# USCI_B0__SPI_Mode_1 register map
Vendor: Texas Instruments
Peripheral module from a debugger description file (folder msp430).
Registers are 8-bit, access not given, no defined reset value unless marked. A register's access mark holds for its fields unless they carry their own. Offsets are as the file gives them; lines under a group give offsets from that group; [hi:lo] are bit positions; {n}, {i} and the like mark numbered series; 'fields as' and 'values as' point back to an identical list; <NAME> marks a mode.

## USCI_B0_SPI_Mode
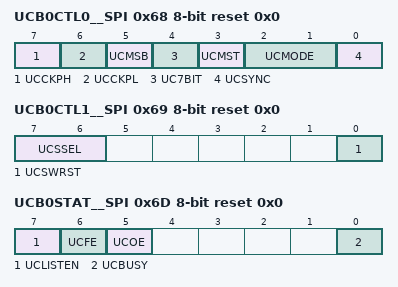
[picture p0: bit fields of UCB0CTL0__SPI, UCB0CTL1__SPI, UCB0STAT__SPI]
0x68 UCB0CTL0__SPI rw reset 0x0 — USCI B0 Control Register 0
  [7] UCCKPH — Sync. Mode: Clock Phase
  [6] UCCKPL — Sync. Mode: Clock Polarity
  [5] UCMSB — Sync. Mode: MSB first 0:LSB / 1:MSB
  [4] UC7BIT — Sync. Mode: Data Bits 0:8-bits / 1:7-bits
  [3] UCMST — Sync. Mode: Master Select
  [2:1] UCMODE — Sync. Mode: USCI Mode 1
    {v}=Sync. Mode: USCI Mode: {v} (v=0..3)
  [0] UCSYNC — Sync-Mode 0:UART-Mode / 1:SPI-Mode
0x69 UCB0CTL1__SPI rw reset 0x0 — USCI B0 Control Register 1
  [7:6] UCSSEL — USCI 1 Clock Source Select 1
    {v}=USCI 0 Clock Source: {v} (v=0..3)
  [0] UCSWRST — USCI Software Reset
0x6A UCB0BR0__SPI — USCI B0 Baud Rate 0
0x6B UCB0BR1__SPI — USCI B0 Baud Rate 1
0x6D UCB0STAT__SPI rw reset 0x0 — USCI B0 Status Register
  [7] UCLISTEN — USCI Listen mode
  [6] UCFE — USCI Frame Error Flag
  [5] UCOE — USCI Overrun Error Flag
  [0] UCBUSY — USCI Busy Flag
0x6E UCB0RXBUF__SPI — USCI B0 Receive Buffer
0x6F UCB0TXBUF__SPI — USCI B0 Transmit Buffer
